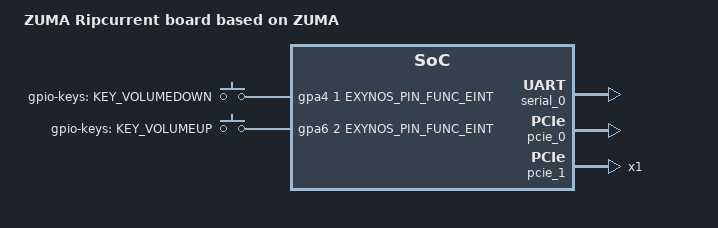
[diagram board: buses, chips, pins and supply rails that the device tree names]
// SPDX-License-Identifier: GPL-2.0-only
/*
 * Ripcurrent board device tree source
 *
 * Copyright 2022 Google LLC
 */

/dts-v1/;
/plugin/;

#include <dt-bindings/interrupt-controller/arm-gic.h>
#include <dt-bindings/pinctrl/gs101.h>
#include <dt-bindings/pinctrl/samsung.h>

#include "zuma-pmic.dtsi"
#include "zuma-typec.dtsi"
#include "zuma-ripcurrent-usb.dtsi"
#include "zuma-ripcurrent-camera-pmic.dtsi"
#include "zuma-ripcurrent-camera.dtsi"
#include "zuma-ripcurrent-display.dtsi"
#include "zuma-ripcurrent-battery.dtsi"
#include "zuma-ripcurrent-charging.dtsi"
#include "zuma-ripcurrent-gsa-gsc.dtsi"
#include "zuma-ripcurrent-touch.dtsi"
#include "zuma-ripcurrent-usecases.dtsi"
#include "zuma-ripcurrent-wcharger.dtsi"
#include "zuma-ripcurrent-wlan.dtsi"
#include "zuma-ripcurrent-cp-s5300-sit.dtsi"
#include "zuma-ripcurrent-audio.dtsi"
#include "zuma-ripcurrent-gps.dtsi"
#include "zuma-ripcurrent-nfc.dtsi"
#include "zuma-ripcurrent-ese.dtsi"

#include <dt-bindings/pci/pci.h>

/ {
	board_id = <0x40101>;
	board_rev = <0x000000>;
	fragment@boardbase {
		target-path = "/";
		__overlay__ {
			model = "ZUMA Ripcurrent board based on ZUMA";
			compatible = "google,ZUMA Ripcurrent", "google,ZUMA";
		};
	};
};

&serial_0 {
	status = "okay";
};

&pinctrl_0 {
	key_voldown: key-voldown {
		samsung,pins = "gpa4-1";
		samsung,pin-function = <EXYNOS_PIN_FUNC_EINT>;
		samsung,pin-pud = <EXYNOS_PIN_PULL_NONE>;
		samsung,pin-drv = <GS101_PIN_DRV_2_5_MA>;
	};

	key_volup: key-volup {
		samsung,pins = "gpa6-2";
		samsung,pin-function = <EXYNOS_PIN_FUNC_EINT>;
		samsung,pin-pud = <EXYNOS_PIN_PULL_NONE>;
		samsung,pin-drv = <GS101_PIN_DRV_2_5_MA>;
	};
};

&gpio_keys {
	status = "okay";
	pinctrl-names = "default";
	pinctrl-0 = <&key_voldown &key_volup>;
	button@1 {
		label = "gpio-keys: KEY_VOLUMEDOWN";
		linux,code = <114>;
		gpios = <&gpa4 1 EXYNOS_PIN_FUNC_EINT>;
		wakeup-source;
	};
	button@2 {
		label = "gpio-keys: KEY_VOLUMEUP";
		linux,code = <115>;
		gpios = <&gpa6 2 EXYNOS_PIN_FUNC_EINT>;
		wakeup-source;
	};
};

&pcie_0 {       /* pcie ch0 used for the connection with CP */
	status = "okay";
	use-cache-coherency = "true";
	use-msi = "true";
	use-sicd = "true";
	use-ia = "false";
	use-l1ss = "false";
	phy-power-off = "false";
	use-pcieon-sleep = "true";
	use-sysmmu = "disabled";
	ep-device-type = <EP_SAMSUNG_MODEM>;
};

&sysmmu_hsi1 {
	use-map-once = "true";
	status = "disabled";
};

&pcie_1 {       /* pcie ch1 used for the connection with WiFi */
	status = "okay";
	num-lanes = <1>;
	use-sicd = "true";
	use-ia = "false";
	use-l1ss = "false";
	use-msi = "true";
	use-sysmmu = "disabled";
	max-link-speed = <LINK_SPEED_GEN2>;
	ep-device-type = <EP_BCM_WIFI>;
	pcie,wlan-gpio = <&gph3 4 0x1 /* WLAN_EN */ >;  /* WLAN_REG_ON */
};
